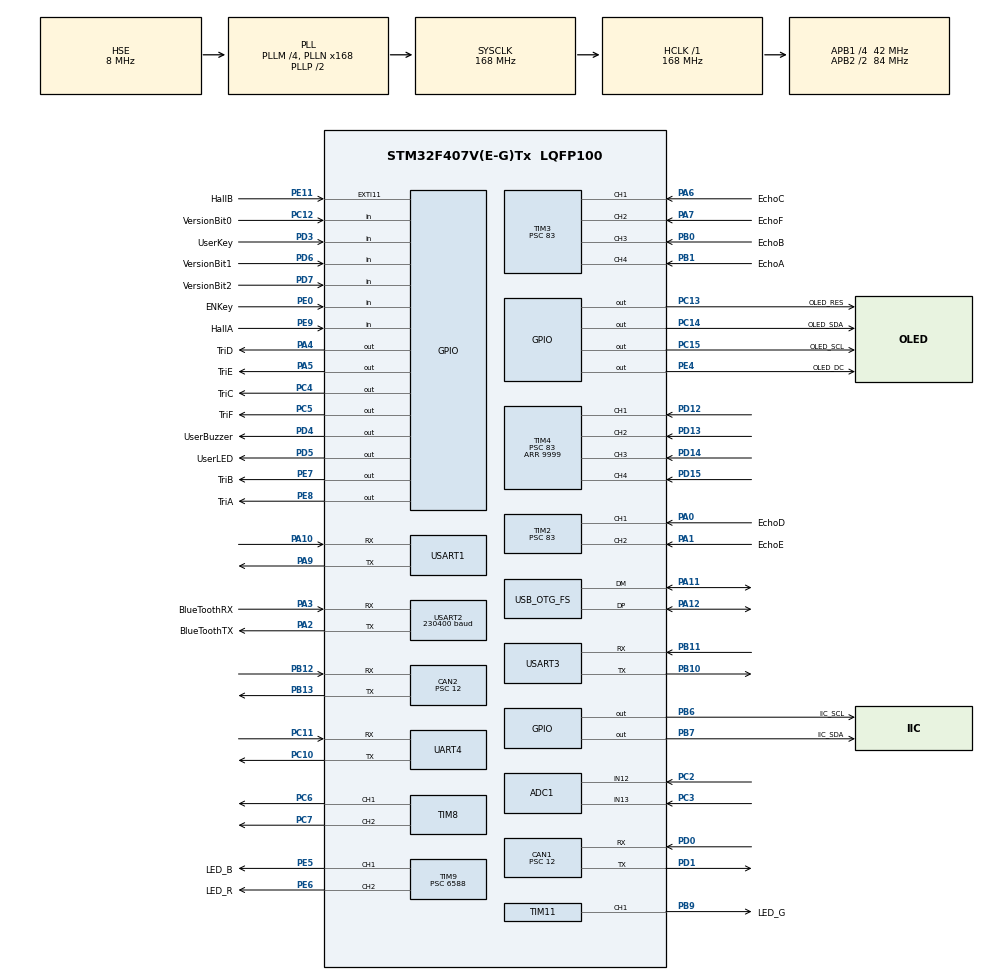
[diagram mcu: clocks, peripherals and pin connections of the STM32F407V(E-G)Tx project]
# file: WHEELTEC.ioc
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ADC1.Channel-0\#ChannelRegularConversion=ADC_CHANNEL_12
ADC1.Channel-1\#ChannelRegularConversion=ADC_CHANNEL_13
ADC1.ClockPrescaler=ADC_CLOCK_SYNC_PCLK_DIV6
ADC1.ContinuousConvMode=ENABLE
ADC1.DMAContinuousRequests=ENABLE
ADC1.NbrOfConversion=2
ADC1.NbrOfConversionFlag=1
ADC1.Rank-0\#ChannelRegularConversion=1
ADC1.Rank-1\#ChannelRegularConversion=2
ADC1.SamplingTime-0\#ChannelRegularConversion=ADC_SAMPLETIME_480CYCLES
ADC1.SamplingTime-1\#ChannelRegularConversion=ADC_SAMPLETIME_480CYCLES
ADC1.ScanConvMode=ENABLE
ADC1.master=1
CAN1.BS1=CAN_BS1_3TQ
CAN1.BS2=CAN_BS2_3TQ
CAN1.CalculateBaudRate=500000
CAN1.CalculateTimeBit=2000
CAN1.CalculateTimeQuantum=285.7142857142857
CAN1.Prescaler=12
CAN1.SJW=CAN_SJW_1TQ
CAN2.BS1=CAN_BS1_3TQ
CAN2.BS2=CAN_BS2_3TQ
CAN2.CalculateBaudRate=500000
CAN2.CalculateTimeBit=2000
CAN2.CalculateTimeQuantum=285.7142857142857
CAN2.Prescaler=12
Dma.ADC1.0.Direction=DMA_PERIPH_TO_MEMORY
Dma.ADC1.0.FIFOMode=DMA_FIFOMODE_DISABLE
Dma.ADC1.0.Instance=DMA2_Stream0
Dma.ADC1.0.MemDataAlignment=DMA_MDATAALIGN_HALFWORD
Dma.ADC1.0.MemInc=DMA_MINC_ENABLE
Dma.ADC1.0.Mode=DMA_CIRCULAR
Dma.ADC1.0.PeriphDataAlignment=DMA_PDATAALIGN_HALFWORD
Dma.ADC1.0.PeriphInc=DMA_PINC_DISABLE
Dma.ADC1.0.Priority=DMA_PRIORITY_LOW
Dma.Request0=ADC1
Dma.Request1=USART2_TX
Dma.Request2=UART4_TX
Dma.Request3=USART1_TX
Dma.Request4=USART3_RX
Dma.UART4_TX.2.Direction=DMA_MEMORY_TO_PERIPH
Dma.UART4_TX.2.FIFOMode=DMA_FIFOMODE_DISABLE
Dma.UART4_TX.2.Instance=DMA1_Stream4
Dma.UART4_TX.2.MemDataAlignment=DMA_MDATAALIGN_BYTE
Dma.UART4_TX.2.MemInc=DMA_MINC_ENABLE
Dma.UART4_TX.2.Mode=DMA_NORMAL
Dma.UART4_TX.2.PeriphDataAlignment=DMA_PDATAALIGN_BYTE
Dma.UART4_TX.2.PeriphInc=DMA_PINC_DISABLE
Dma.UART4_TX.2.Priority=DMA_PRIORITY_LOW
Dma.USART1_TX.3.Direction=DMA_MEMORY_TO_PERIPH
Dma.USART1_TX.3.FIFOMode=DMA_FIFOMODE_DISABLE
Dma.USART1_TX.3.Instance=DMA2_Stream7
Dma.USART1_TX.3.MemDataAlignment=DMA_MDATAALIGN_BYTE
Dma.USART1_TX.3.MemInc=DMA_MINC_ENABLE
Dma.USART1_TX.3.Mode=DMA_NORMAL
Dma.USART1_TX.3.PeriphDataAlignment=DMA_PDATAALIGN_BYTE
Dma.USART1_TX.3.PeriphInc=DMA_PINC_DISABLE
Dma.USART1_TX.3.Priority=DMA_PRIORITY_LOW
Dma.USART2_TX.1.Direction=DMA_MEMORY_TO_PERIPH
Dma.USART2_TX.1.FIFOMode=DMA_FIFOMODE_DISABLE
Dma.USART2_TX.1.Instance=DMA1_Stream6
Dma.USART2_TX.1.MemDataAlignment=DMA_MDATAALIGN_BYTE
Dma.USART2_TX.1.MemInc=DMA_MINC_ENABLE
Dma.USART2_TX.1.Mode=DMA_NORMAL
Dma.USART2_TX.1.PeriphDataAlignment=DMA_PDATAALIGN_BYTE
Dma.USART2_TX.1.PeriphInc=DMA_PINC_DISABLE
Dma.USART2_TX.1.Priority=DMA_PRIORITY_LOW
Dma.USART3_RX.4.Direction=DMA_PERIPH_TO_MEMORY
Dma.USART3_RX.4.FIFOMode=DMA_FIFOMODE_DISABLE
Dma.USART3_RX.4.Instance=DMA1_Stream1
Dma.USART3_RX.4.MemDataAlignment=DMA_MDATAALIGN_BYTE
Dma.USART3_RX.4.MemInc=DMA_MINC_ENABLE
Dma.USART3_RX.4.Mode=DMA_NORMAL
Dma.USART3_RX.4.PeriphDataAlignment=DMA_PDATAALIGN_BYTE
Dma.USART3_RX.4.PeriphInc=DMA_PINC_DISABLE
Dma.USART3_RX.4.Priority=DMA_PRIORITY_LOW
FREERTOS.Tasks01=InitTask,32,128,StartInitTask,Default,NULL,Dynamic,NULL,NULL
FREERTOS.configCHECK_FOR_STACK_OVERFLOW=2
FREERTOS.configENABLE_FPU=1
FREERTOS.configGENERATE_RUN_TIME_STATS=1
FREERTOS.configTOTAL_HEAP_SIZE=51200
FREERTOS.configUSE_DAEMON_TASK_STARTUP_HOOK=0
FREERTOS.configUSE_IDLE_HOOK=1
FREERTOS.configUSE_MALLOC_FAILED_HOOK=1
FREERTOS.configUSE_STATS_FORMATTING_FUNCTIONS=1
Mcu.Family=STM32F4
Mcu.Name=STM32F407V(E-G)Tx
Mcu.Package=LQFP100
NVIC.CAN1_RX0_IRQn=true\:5\:0\:false\:false\:true\:true\:true\:true\:true
NVIC.CAN2_RX1_IRQn=true\:5\:0\:false\:false\:true\:true\:true\:true\:true
NVIC.DMA1_Stream1_IRQn=true\:5\:0\:false\:false\:true\:true\:false\:true\:true
NVIC.DMA1_Stream4_IRQn=true\:5\:0\:false\:false\:true\:true\:false\:true\:true
NVIC.DMA1_Stream6_IRQn=true\:5\:0\:false\:false\:true\:true\:false\:true\:true
NVIC.DMA2_Stream0_IRQn=true\:5\:0\:false\:false\:true\:true\:false\:true\:true
NVIC.DMA2_Stream7_IRQn=true\:5\:0\:false\:false\:true\:true\:false\:true\:true
NVIC.EXTI9_5_IRQn=true\:5\:0\:false\:false\:true\:true\:true\:true\:true
NVIC.OTG_FS_IRQn=true\:5\:0\:false\:false\:true\:true\:false\:true\:true
NVIC.PriorityGroup=NVIC_PRIORITYGROUP_4
NVIC.TIM2_IRQn=true\:5\:0\:false\:false\:true\:true\:true\:true\:true
NVIC.TIM3_IRQn=true\:5\:0\:false\:false\:true\:true\:true\:true\:true
NVIC.TIM4_IRQn=true\:5\:0\:false\:false\:true\:true\:true\:true\:true
NVIC.TIM7_IRQn=true\:15\:0\:true\:false\:true\:false\:false\:true\:true
NVIC.TimeBase=TIM7_IRQn
NVIC.TimeBaseIP=TIM7
NVIC.UART4_IRQn=true\:5\:0\:false\:false\:true\:true\:true\:true\:true
NVIC.USART1_IRQn=true\:5\:0\:false\:false\:true\:true\:true\:true\:true
NVIC.USART2_IRQn=true\:5\:0\:false\:false\:true\:true\:true\:true\:true
NVIC.USART3_IRQn=true\:5\:0\:false\:false\:true\:true\:true\:true\:true
PA0-WKUP.GPIO_Label=EchoD
PA0-WKUP.Signal=S_TIM2_CH1_ETR
PA1.GPIO_Label=EchoE
PA1.Signal=S_TIM2_CH2
PA10.Mode=Asynchronous
PA10.Signal=USART1_RX
PA11.Mode=Host_Only
PA11.Signal=USB_OTG_FS_DM
PA12.Mode=Host_Only
PA12.Signal=USB_OTG_FS_DP
PA13.Mode=Serial_Wire
PA13.Signal=SYS_JTMS-SWDIO
PA14.Mode=Serial_Wire
PA14.Signal=SYS_JTCK-SWCLK
PA2.GPIO_Label=BlueToothTX
PA2.Mode=Asynchronous
PA2.Signal=USART2_TX
PA3.GPIO_Label=BlueToothRX
PA3.Mode=Asynchronous
PA3.Signal=USART2_RX
PA4.GPIO_Label=TriD
PA4.GPIO_Speed=GPIO_SPEED_FREQ_VERY_HIGH
PA4.PinState=GPIO_PIN_SET
PA4.Signal=GPIO_Output
PA5.GPIO_Label=TriE
PA5.GPIO_Speed=GPIO_SPEED_FREQ_VERY_HIGH
PA5.PinState=GPIO_PIN_SET
PA5.Signal=GPIO_Output
PA6.GPIO_Label=EchoC
PA6.Signal=S_TIM3_CH1
PA7.GPIO_Label=EchoF
PA7.Signal=S_TIM3_CH2
PA9.Mode=Asynchronous
PA9.Signal=USART1_TX
PB0.GPIO_Label=EchoB
PB0.Signal=S_TIM3_CH3
PB1.GPIO_Label=EchoA
PB1.Signal=S_TIM3_CH4
PB10.Mode=Asynchronous
PB10.Signal=USART3_TX
PB11.Mode=Asynchronous
PB11.Signal=USART3_RX
PB12.Mode=CAN_Activate
PB12.Signal=CAN2_RX
PB13.Mode=CAN_Activate
PB13.Signal=CAN2_TX
PB6.GPIO_Label=IIC_SCL
PB6.GPIO_PuPd=GPIO_NOPULL
PB6.GPIO_Speed=GPIO_SPEED_FREQ_VERY_HIGH
PB6.PinState=GPIO_PIN_SET
PB6.Signal=GPIO_Output
PB7.GPIO_Label=IIC_SDA
PB7.GPIO_Speed=GPIO_SPEED_FREQ_VERY_HIGH
PB7.PinState=GPIO_PIN_SET
PB7.Signal=GPIO_Output
PB9.GPIO_Label=LED_G
PB9.Signal=S_TIM11_CH1
PC10.Mode=Asynchronous
PC10.Signal=UART4_TX
PC11.Mode=Asynchronous
PC11.Signal=UART4_RX
PC12.GPIO_Label=VersionBit0
PC12.GPIO_PuPd=GPIO_PULLUP
PC12.Signal=GPIO_Input
PC13-ANTI_TAMP.GPIO_Label=OLED_RES
PC13-ANTI_TAMP.Signal=GPIO_Output
PC14-OSC32_IN.GPIO_Label=OLED_SDA
PC14-OSC32_IN.Signal=GPIO_Output
PC15-OSC32_OUT.GPIO_Label=OLED_SCL
PC15-OSC32_OUT.Signal=GPIO_Output
PC2.Signal=ADCx_IN12
PC3.Signal=ADCx_IN13
PC4.GPIO_Label=TriC
PC4.GPIO_Speed=GPIO_SPEED_FREQ_VERY_HIGH
PC4.PinState=GPIO_PIN_SET
PC4.Signal=GPIO_Output
PC5.GPIO_Label=TriF
PC5.GPIO_Speed=GPIO_SPEED_FREQ_VERY_HIGH
PC5.PinState=GPIO_PIN_SET
PC5.Signal=GPIO_Output
PC6.Signal=S_TIM8_CH1
PC7.Signal=S_TIM8_CH2
PD0.Mode=CAN_Activate
PD0.Signal=CAN1_RX
PD1.Mode=CAN_Activate
PD1.Signal=CAN1_TX
PD12.Signal=S_TIM4_CH1
PD13.Signal=S_TIM4_CH2
PD14.Signal=S_TIM4_CH3
PD15.Signal=S_TIM4_CH4
PD3.GPIO_Label=UserKey
PD3.GPIO_PuPd=GPIO_PULLUP
PD3.Signal=GPIO_Input
PD4.GPIO_Label=UserBuzzer
PD4.PinState=GPIO_PIN_RESET
PD4.Signal=GPIO_Output
PD5.GPIO_Label=UserLED
PD5.PinState=GPIO_PIN_SET
PD5.Signal=GPIO_Output
PD6.GPIO_Label=VersionBit1
PD6.GPIO_PuPd=GPIO_PULLUP
PD6.Signal=GPIO_Input
PD7.GPIO_Label=VersionBit2
PD7.GPIO_PuPd=GPIO_PULLUP
PD7.Signal=GPIO_Input
PE0.GPIO_Label=ENKey
PE0.GPIO_Mode=GPIO_MODE_INPUT
PE0.GPIO_PuPd=GPIO_PULLUP
PE0.Signal=GPIO_Input
PE4.GPIO_Label=OLED_DC
PE4.Signal=GPIO_Output
PE5.GPIO_Label=LED_B
PE5.Signal=S_TIM9_CH1
PE6.GPIO_Label=LED_R
PE6.Signal=S_TIM9_CH2
PE7.GPIO_Label=TriB
PE7.GPIO_Speed=GPIO_SPEED_FREQ_VERY_HIGH
PE7.PinState=GPIO_PIN_SET
PE7.Signal=GPIO_Output
PE8.GPIO_Label=TriA
PE8.GPIO_Speed=GPIO_SPEED_FREQ_VERY_HIGH
PE8.PinState=GPIO_PIN_SET
PE8.Signal=GPIO_Output
PE9.GPIO_Label=HallA
PE9.GPIO_Mode=GPIO_MODE_INPUT
PE9.GPIO_PuPd=GPIO_PULLUP
PE9.Signal=GPIO_Input
PE11.GPIO_Label=HallB
PE11.GPIO_Mode=GPIO_MODE_IT_FALLING
PE11.GPIO_PuPd=GPIO_PULLUP
PE11.Signal=GPIO_EXTI11
PH0-OSC_IN.Mode=HSE-External-Oscillator
PH0-OSC_IN.Signal=RCC_OSC_IN
PH1-OSC_OUT.Mode=HSE-External-Oscillator
PH1-OSC_OUT.Signal=RCC_OSC_OUT
ProjectManager.HeapSize=0x200
ProjectManager.StackSize=0x400
ProjectManager.TargetToolchain=MDK-ARM V5.32
RCC.48MHZClocksFreq_Value=48000000
RCC.AHBFreq_Value=168000000
RCC.APB1CLKDivider=RCC_HCLK_DIV4
RCC.APB1Freq_Value=42000000
RCC.APB1TimFreq_Value=84000000
RCC.APB2CLKDivider=RCC_HCLK_DIV2
RCC.APB2Freq_Value=84000000
RCC.APB2TimFreq_Value=168000000
RCC.CortexFreq_Value=168000000
RCC.HCLKFreq_Value=168000000
RCC.HSE_VALUE=8000000
RCC.HSI_VALUE=16000000
RCC.LSE_VALUE=32768
RCC.PLLM=4
RCC.PLLN=168
RCC.PLLQ=7
RCC.SYSCLKFreq_VALUE=168000000
RCC.SYSCLKSource=RCC_SYSCLKSOURCE_PLLCLK
RCC.VCOOutputFreq_Value=336000000
SH.ADCx_IN12.0=ADC1_IN12,IN12
SH.ADCx_IN13.0=ADC1_IN13,IN13
SH.S_TIM11_CH1.0=TIM11_CH1,PWM Generation1 CH1
SH.S_TIM2_CH1_ETR.0=TIM2_CH1,Input_Capture1_from_TI1
SH.S_TIM2_CH2.0=TIM2_CH2,Input_Capture2_from_TI2
SH.S_TIM3_CH1.0=TIM3_CH1,Input_Capture1_from_TI1
SH.S_TIM3_CH2.0=TIM3_CH2,Input_Capture2_from_TI2
SH.S_TIM3_CH3.0=TIM3_CH3,Input_Capture3_from_TI3
SH.S_TIM3_CH4.0=TIM3_CH4,Input_Capture4_from_TI4
SH.S_TIM4_CH1.0=TIM4_CH1,Input_Capture1_from_TI1
SH.S_TIM4_CH2.0=TIM4_CH2,Input_Capture2_from_TI2
SH.S_TIM4_CH3.0=TIM4_CH3,Input_Capture3_from_TI3
SH.S_TIM4_CH4.0=TIM4_CH4,Input_Capture4_from_TI4
SH.S_TIM8_CH1.0=TIM8_CH1,PWM Generation1 CH1
SH.S_TIM8_CH2.0=TIM8_CH2,PWM Generation2 CH2
SH.S_TIM9_CH1.0=TIM9_CH1,PWM Generation1 CH1
SH.S_TIM9_CH2.0=TIM9_CH2,PWM Generation2 CH2
TIM11.Channel=TIM_CHANNEL_1
TIM11.Period=254
TIM11.Prescaler=6588
TIM2.Channel-Input_Capture1_from_TI1=TIM_CHANNEL_1
TIM2.Channel-Input_Capture2_from_TI2=TIM_CHANNEL_2
TIM2.Period=0xffff
TIM2.Prescaler=83
TIM3.Channel-Input_Capture1_from_TI1=TIM_CHANNEL_1
TIM3.Channel-Input_Capture2_from_TI2=TIM_CHANNEL_2
TIM3.Channel-Input_Capture3_from_TI3=TIM_CHANNEL_3
TIM3.Channel-Input_Capture4_from_TI4=TIM_CHANNEL_4
TIM3.Prescaler=83
TIM4.Channel-Input_Capture1_from_TI1=TIM_CHANNEL_1
TIM4.Channel-Input_Capture2_from_TI2=TIM_CHANNEL_2
TIM4.Channel-Input_Capture3_from_TI3=TIM_CHANNEL_3
TIM4.Channel-Input_Capture4_from_TI4=TIM_CHANNEL_4
TIM4.Period=9999
TIM4.Prescaler=83
TIM6.Prescaler=839
TIM8.Channel-PWM\ Generation1\ CH1=TIM_CHANNEL_1
TIM8.Channel-PWM\ Generation2\ CH2=TIM_CHANNEL_2
TIM9.Channel-PWM\ Generation1\ CH1=TIM_CHANNEL_1
TIM9.Channel-PWM\ Generation2\ CH2=TIM_CHANNEL_2
TIM9.Period=254
TIM9.Prescaler=6588
UART4.VirtualMode=Asynchronous
USART1.VirtualMode=VM_ASYNC
USART2.BaudRate=230400
USART2.VirtualMode=VM_ASYNC
USART3.VirtualMode=VM_ASYNC
USB_HOST.SW_VBUS_DRIVE_HID_FS=true
USB_HOST.USBH_DEBUG_LEVEL-HID_FS=0
USB_HOST.USBH_HandleTypeDef-HID_FS=hUsbHostFS
USB_HOST.USBH_MAX_DATA_BUFFER-HID_FS=2048
USB_HOST.USBH_MAX_NUM_SUPPORTED_CLASS-HID_FS=2
USB_HOST.USBH_MAX_SIZE_CONFIGURATION-HID_FS=256
USB_HOST.USBH_PROCESS_STACK_SIZE-HID_FS=1024
USB_HOST.VirtualModeFS=Hid
USB_OTG_FS.VirtualMode=Host_Only
USB_OTG_FS.phy_itface=HCD_PHY_EMBEDDED
VP_FREERTOS_VS_CMSIS_V2.Mode=CMSIS_V2
VP_SYS_VS_tim7.Mode=TIM7
VP_TIM11_VS_ClockSourceINT.Mode=Enable_Timer
VP_TIM2_VS_ClockSourceINT.Mode=Internal
VP_TIM3_VS_ClockSourceINT.Mode=Internal
VP_TIM4_VS_ClockSourceINT.Mode=Internal
VP_TIM6_VS_ClockSourceINT.Mode=Enable_Timer
VP_TIM8_VS_ClockSourceINT.Mode=Internal
VP_TIM9_VS_ClockSourceINT.Mode=Internal
VP_USB_HOST_VS_USB_HOST_HID_FS.Mode=HID_FS
board=custom

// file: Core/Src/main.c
/* USER CODE BEGIN Header */
/**
  ******************************************************************************
  * @file           : main.c
  * @brief          : Main program body
  ******************************************************************************
  * @attention
  *
  * Copyright (c) 2025 STMicroelectronics.
  * All rights reserved.
  *
  * This software is licensed under terms that can be found in the LICENSE file
  * in the root directory of this software component.
  * If no LICENSE file comes with this software, it is provided AS-IS.
  *
  ******************************************************************************
  */
/* USER CODE END Header */
#include "main.h"
#include "cmsis_os.h"
#include "adc.h"
#include "can.h"
#include "dma.h"
#include "tim.h"
#include "usart.h"
#include "usb_host.h"
#include "gpio.h"

/* USER CODE BEGIN Includes */
#include <stdio.h>

//bsp
#include "bsp_oled.h"
#include "bsp_dwt.h"
#include "bsp_can.h"
#include "bsp_adc.h"
#include "bsp_flash.h"

#include "hall_speed.h"
#include "servo_basic_control.h"
#include "robot_select_init.h"

/* USER CODE END Includes */

/* USER CODE BEGIN PV */

static uint8_t HardWareVersion = HW_UnKnown; //绯荤粺纭欢鐗堟湰

uint8_t BlueToothBuffer = 0;//钃濈墮涓插彛鎺ユ敹缂撳啿
uint8_t rosbuffer = 0;      //ROS涓插彛鎺ユ敹缂撳啿鍖?
uint8_t usart1_buffer = 0;  //涓插彛1鎺ユ敹缂撳啿鍖?
uint8_t rs485_buffer = 0;   //485鎺ユ敹缂撳啿鍖?

DebugType_t g_sys_debug = { 0 }; //鍏ㄥ眬璋冭瘯鍙橀噺
/* USER CODE END PV */

void SystemClock_Config(void);
void MX_FREERTOS_Init(void);

int main(void)
{

  /* MCU Configuration--------------------------------------------------------*/

  /* Reset of all peripherals, Initializes the Flash interface and the Systick. */
  HAL_Init();

  /* Configure the system clock */
  SystemClock_Config();

  /* Initialize all configured peripherals */
  MX_GPIO_Init();
  MX_DMA_Init();
  MX_USART1_UART_Init();
  MX_USART2_UART_Init();
  MX_USART3_UART_Init();
  MX_UART4_Init();
  MX_TIM2_Init();
  MX_TIM3_Init();
  MX_TIM4_Init();
  MX_TIM6_Init();
  MX_TIM9_Init();
  MX_TIM11_Init();
  MX_ADC1_Init();
  MX_CAN1_Init();
  MX_CAN2_Init();
  MX_TIM8_Init();
  /* USER CODE BEGIN 2 */

  /* Initialize Ackermann servo/ESC control state */
  ServoBasic_Init();

		//DWT瀹氭椂鍣ㄥ垵濮嬪寲,鐢ㄤ簬瀹炵幇ms銆乽s寤舵椂鍑芥暟
		DWT_Init();

		//鍒濆鍖栭湇灏旇疆閫熺姸鎬侊紝璇ュ姛鑳藉湪 PE9/PE11 EXTI 杈撳叆涓婂伐浣?
		HallSpeed_Init();

		//ADC鐢ㄦ埛閰嶇疆鍒濆鍖?
		ADC_Userconfig_Init();

	//鍚姩FreeRTOS绯荤粺璋冭瘯瀹氭椂鍣?
	HAL_TIM_Base_Start(&htim6);

	//OLED灞忓箷鍒濆鍖?
	pOLEDInterface_t oled = &UserOLED;
	oled->init();

	//C63X纭欢鐗堟湰纭畾(閫氳繃鐗堟湰io鍙?纭纭欢鐗堟湰)
	uint8_t Version = 0;
	Version |= (HAL_GPIO_ReadPin(VersionBit2_GPIO_Port,VersionBit2_Pin))<<2;
	Version |= (HAL_GPIO_ReadPin(VersionBit1_GPIO_Port,VersionBit1_Pin))<<1;
	Version |= (HAL_GPIO_ReadPin(VersionBit0_GPIO_Port,VersionBit0_Pin))<<0;

	if( Version == 0 )
	{
		HardWareVersion = HW_1_1;
	}
	else if( Version == 7)
	{
		HardWareVersion = HW_1_0;

		//鍙嶅垵濮嬪寲V2.0鐗堟湰鐨凜AN寮曡剼
		HAL_GPIO_DeInit(GPIOD, GPIO_PIN_0|GPIO_PIN_1);

		//鍒濆鍖朧1.0鐗堟湰CAN寮曡剼
		GPIO_InitTypeDef GPIO_InitStruct = {0};
		__HAL_RCC_GPIOA_CLK_ENABLE();
		GPIO_InitStruct.Pin = GPIO_PIN_11|GPIO_PIN_12;
		GPIO_InitStruct.Mode = GPIO_MODE_AF_PP;
		GPIO_InitStruct.Pull = GPIO_NOPULL;
		GPIO_InitStruct.Speed = GPIO_SPEED_FREQ_VERY_HIGH;
		GPIO_InitStruct.Alternate = GPIO_AF9_CAN1;
		HAL_GPIO_Init(GPIOA, &GPIO_InitStruct);

		//V1.0鐗堟湰鎬ュ仠寮€鍏?
		HAL_GPIO_DeInit(ENKey_GPIO_Port,ENKey_Pin);
		__HAL_RCC_GPIOD_CLK_ENABLE();
		GPIO_InitStruct.Pin = ENKey_V1_0_Pin;
		GPIO_InitStruct.Mode = GPIO_MODE_INPUT;
		GPIO_InitStruct.Pull = GPIO_PULLUP;
		HAL_GPIO_Init(ENKey_V1_0_GPIO_Port, &GPIO_InitStruct);

		//V1.0鐗堟湰鎸夐敭
		HAL_GPIO_DeInit(UserKey_V1_0_Port,UserKey_V1_0_Pin);
		HAL_GPIO_DeInit(UserKey_GPIO_Port,UserKey_Pin);
		__HAL_RCC_GPIOD_CLK_ENABLE();
		GPIO_InitStruct.Pin = UserKey_V1_0_Pin;
		GPIO_InitStruct.Mode = GPIO_MODE_INPUT;
		GPIO_InitStruct.Pull = GPIO_PULLUP;
		HAL_GPIO_Init(UserKey_V1_0_Port, &GPIO_InitStruct);
	}
	else
	{
		oled->ShowString(0,0,"unknown hardware-version.");
		oled->ShowString(0,35,"please reset and-retry.");
		oled->RefreshGram();
		while(1)
		{
			HAL_GPIO_TogglePin(UserBuzzer_GPIO_Port,UserBuzzer_Pin);
			HAL_Delay(500);
		}
	}

	//寮€鍚埅妯￠仴鎺х浉鍏冲畾鏃跺櫒鎹曡幏鍔熻兘
	HAL_TIM_IC_Start_IT(&htim4,TIM_CHANNEL_1);
	HAL_TIM_IC_Start_IT(&htim4,TIM_CHANNEL_2);
	HAL_TIM_IC_Start_IT(&htim4,TIM_CHANNEL_3);

	//鍚姩涓插彛鎺ユ敹涓柇
	HAL_UART_Receive_IT(&huart2,&BlueToothBuffer,1);
	HAL_UART_Receive_IT(&huart4,&rosbuffer,1);
	HAL_UART_Receive_IT(&huart1,&usart1_buffer,1);
	HAL_UART_Receive_IT(&huart3,&rs485_buffer,1);

	//485鎺ュ彛娴嬭瘯浣跨敤
//	uint8_t _485debug[] = {"hello c63x! RS485 Test Info"};
//	HAL_UART_Transmit(&huart3,_485debug,sizeof(_485debug)/sizeof(_485debug[0]),500);

	//閫氳繃鐢典綅鍣ㄧ‘璁よ溅鍨?
	HAL_Delay(500);
	Robot_Select();

	//璇诲彇鐢ㄦ埛淇濆瓨鐨勯粯璁ら€熷害鍊?
	uint32_t flashdata[2];
	User_Flash_ReadParam((uint32_t *)flashdata,2);

	//灏忚溅榛樿閬ユ帶閫熷害鍊?
	if( flashdata[0]!=0xFFFFFFFF )
	{
		if( flashdata[0]<=3500 )
			RobotControlParam.defalutSpeed = flashdata[0];
	}

	//绾犲亸绯绘暟鍊?
	if( flashdata[1]!=0xFFFFFFFF )
	{
		if( flashdata[1]<=100 )
			RobotControlParam.LineDiffParam = flashdata[1];
	}

  /* USER CODE END 2 */

  /* Init scheduler */
  osKernelInitialize();  /* Call init function for freertos objects (in cmsis_os2.c) */
  MX_FREERTOS_Init();

  /* Start scheduler */
  osKernelStart();

  /* We should never get here as control is now taken by the scheduler */

  /* Infinite loop */
  while (1)
  {

  }
}

void SystemClock_Config(void)
{
  RCC_OscInitTypeDef RCC_OscInitStruct = {0};
  RCC_ClkInitTypeDef RCC_ClkInitStruct = {0};

  /** Configure the main internal regulator output voltage
  */
  __HAL_RCC_PWR_CLK_ENABLE();
  __HAL_PWR_VOLTAGESCALING_CONFIG(PWR_REGULATOR_VOLTAGE_SCALE1);

  /** Initializes the RCC Oscillators according to the specified parameters
  * in the RCC_OscInitTypeDef structure.
  */
  RCC_OscInitStruct.OscillatorType = RCC_OSCILLATORTYPE_HSE;
  RCC_OscInitStruct.HSEState = RCC_HSE_ON;
  RCC_OscInitStruct.PLL.PLLState = RCC_PLL_ON;
  RCC_OscInitStruct.PLL.PLLSource = RCC_PLLSOURCE_HSE;
  RCC_OscInitStruct.PLL.PLLM = 4;
  RCC_OscInitStruct.PLL.PLLN = 168;
  RCC_OscInitStruct.PLL.PLLP = RCC_PLLP_DIV2;
  RCC_OscInitStruct.PLL.PLLQ = 7;
  if (HAL_RCC_OscConfig(&RCC_OscInitStruct) != HAL_OK)
  {
    Error_Handler();
  }

  /** Initializes the CPU, AHB and APB buses clocks
  */
  RCC_ClkInitStruct.ClockType = RCC_CLOCKTYPE_HCLK|RCC_CLOCKTYPE_SYSCLK
                              |RCC_CLOCKTYPE_PCLK1|RCC_CLOCKTYPE_PCLK2;
  RCC_ClkInitStruct.SYSCLKSource = RCC_SYSCLKSOURCE_PLLCLK;
  RCC_ClkInitStruct.AHBCLKDivider = RCC_SYSCLK_DIV1;
  RCC_ClkInitStruct.APB1CLKDivider = RCC_HCLK_DIV4;
  RCC_ClkInitStruct.APB2CLKDivider = RCC_HCLK_DIV2;

  if (HAL_RCC_ClockConfig(&RCC_ClkInitStruct, FLASH_LATENCY_5) != HAL_OK)
  {
    Error_Handler();
  }
}

/* USER CODE BEGIN 4 */

UART_HandleTypeDef *DebugSerial = &huart1;

//printf鍑芥暟瀹炵幇
int fputc(int ch,FILE* stream)
{
	while( HAL_OK != HAL_UART_Transmit(DebugSerial,(const uint8_t *)&ch,1,100));
	return ch;
}

//鑾峰彇纭欢鐗堟湰
uint8_t get_HardWareVersion(void)
{
	return HardWareVersion;
}

//鑾峰彇鎬ュ仠寮€鍏崇姸鎬?涓庣増鏈浉鍏?
GPIO_PinState get_EnKeyState(void)
{
	if( HardWareVersion == HW_1_0 )
	{
		return HAL_GPIO_ReadPin(ENKey_V1_0_GPIO_Port,ENKey_V1_0_Pin);
	}
	else if( HardWareVersion == HW_1_1 )
	{
		return HAL_GPIO_ReadPin(ENKey_GPIO_Port,ENKey_Pin);
	}

	return GPIO_PIN_RESET;
}

/* USER CODE END 4 */

void HAL_TIM_PeriodElapsedCallback(TIM_HandleTypeDef *htim)
{
  if (htim->Instance == TIM7)
  {
    HAL_IncTick();
  }
}

void Error_Handler(void)
{
  __disable_irq();
  while (1)
  {
  }
}

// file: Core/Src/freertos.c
/* USER CODE BEGIN Header */
/**
  ******************************************************************************
  * File Name          : freertos.c
  * Description        : Code for freertos applications
  ******************************************************************************
  * @attention
  *
  * Copyright (c) 2025 STMicroelectronics.
  * All rights reserved.
  *
  * This software is licensed under terms that can be found in the LICENSE file
  * in the root directory of this software component.
  * If no LICENSE file comes with this software, it is provided AS-IS.
  *
  ******************************************************************************
  */
/* USER CODE END Header */

#include "FreeRTOS.h"
#include "task.h"
#include "main.h"
#include "cmsis_os.h"

/* USER CODE BEGIN Includes */

//C Include File
#include <stdio.h>

//FreeRTOS Include File
#include "queue.h"

//BSP Include File
#include "bsp_oled.h"
#include "bsp_RTOSdebug.h"
#include "bsp_ServoDrive.h"
#include "bsp_RGBLight.h"
#include "bsp_can.h"
#include "bsp_ServoDrive.h"
#include "bsp_buzzer.h"

//APP Include File
#include "sensor_ranger.h"
#include "robot_select_init.h"
#include "servo_basic_task.h"

/* USER CODE END Includes */

/* USER CODE BEGIN PD */

//FreeRTOS系统调试
#define userconfig_OPEN_STACK_CHECK     0  //开启任务栈大小检查打印
#define userconfig_OPEN_CPU_USAGE_CHECK 0  //开启检查CPU占比打印
#define userconfig_OPEN_CHECK_HEAPSIZE  0  //检查剩余的堆大小

/* USER CODE END PD */

/* USER CODE BEGIN Variables */

QueueHandle_t g_xQueueCANopenCallback = NULL;

//蓝牙数据队列
QueueHandle_t g_xQueueBlueTooth = NULL;

//ROS数据队列
QueueHandle_t  g_xQueueROSserial = NULL;

//自动回充队列数据
QueueHandle_t g_xQueueAutoRecharge = NULL;

TaskHandle_t g_reportErrTaskHandle = NULL;

/* USER CODE END Variables */
/* Definitions for InitTask */
osThreadId_t InitTaskHandle;
const osThreadAttr_t InitTask_attributes = {
  .name = "InitTask",
  .stack_size = 128 * 4,
  .priority = (osPriority_t) osPriorityAboveNormal,
};

/* USER CODE BEGIN FunctionPrototypes */

//FreeRTOS系统调试任务
#if ( 1 == userconfig_OPEN_CPU_USAGE_CHECK ) || ( 1 == userconfig_OPEN_STACK_CHECK ) || ( 1 == userconfig_OPEN_CHECK_HEAPSIZE )
void CpuUsageCheckTask(void *param);
#endif

//任务函数声明
void ultrasonic_task(void* param);
void show_task(void* param);
void ImuTask(void* param);
void BlueToothControlTask(void* param);
void SerialControlTask(void* param);
void RobotControl_task(void* param);
void AutoRechargeTask(void* param);
void data_task(void* param);
void RobotDataTransmitTask(void* param);
void APPshow_task(void* param);
void HeartbeatTask(void* param);
void ReportErrTask(void* param);
void RGBControl_task(void* param);

/* USER CODE END FunctionPrototypes */

void StartInitTask(void *argument);

extern void MX_USB_HOST_Init(void);
void MX_FREERTOS_Init(void); /* (MISRA C 2004 rule 8.1) */

/* Hook prototypes */
void configureTimerForRunTimeStats(void);
unsigned long getRunTimeCounterValue(void);
void vApplicationIdleHook(void);
void vApplicationStackOverflowHook(xTaskHandle xTask, signed char *pcTaskName);
void vApplicationMallocFailedHook(void);

/* USER CODE BEGIN 1 */
/* Functions needed when configGENERATE_RUN_TIME_STATS is on */
__weak void configureTimerForRunTimeStats(void)
{
	//使用cpu占比计时器前初始化内容
	TIM6->CNT = 0;
}

__weak unsigned long getRunTimeCounterValue(void)
{
	static unsigned long time = 0 ;
	static uint16_t lasttime = 0;
	static uint16_t nowtime = 0;

	nowtime = TIM6->CNT; //获得当前计数值

	//如果本次计数值小于上次计数值，说明发生了定时器计数溢出
	if( nowtime < lasttime )
	{
		time += (nowtime + 0xffff - lasttime); //溢出后的时间增量
	}
	else time += ( nowtime - lasttime ) ; //未发生溢出，增量为本次时间-上次时间

	lasttime = nowtime;

	return time;
}
/* USER CODE END 1 */

/* USER CODE BEGIN 2 */
void vApplicationIdleHook( void )
{
   /* vApplicationIdleHook() will only be called if configUSE_IDLE_HOOK is set
   to 1 in FreeRTOSConfig.h. It will be called on each iteration of the idle
   task. It is essential that code added to this hook function never attempts
   to block in any way (for example, call xQueueReceive() with a block time
   specified, or call vTaskDelay()). If the application makes use of the
   vTaskDelete() API function (as this demo application does) then it is also
   important that vApplicationIdleHook() is permitted to return to its calling
   function, because it is the responsibility of the idle task to clean up
   memory allocated by the kernel to any task that has since been deleted. */

	//空闲任务钩子函数
}
/* USER CODE END 2 */

/* USER CODE BEGIN 4 */
void vApplicationStackOverflowHook(xTaskHandle xTask, signed char *pcTaskName)
{
   /* Run time stack overflow checking is performed if
   configCHECK_FOR_STACK_OVERFLOW is defined to 1 or 2. This hook function is
   called if a stack overflow is detected. */

	//任务栈溢出警告
	printf("%s stack overflow\r\n",pcTaskName);
}
/* USER CODE END 4 */

/* USER CODE BEGIN 5 */
void vApplicationMallocFailedHook(void)
{
   /* vApplicationMallocFailedHook() will only be called if
   configUSE_MALLOC_FAILED_HOOK is set to 1 in FreeRTOSConfig.h. It is a hook
   function that will get called if a call to pvPortMalloc() fails.
   pvPortMalloc() is called internally by the kernel whenever a task, queue,
   timer or semaphore is created. It is also called by various parts of the
   demo application. If heap_1.c or heap_2.c are used, then the size of the
   heap available to pvPortMalloc() is defined by configTOTAL_HEAP_SIZE in
   FreeRTOSConfig.h, and the xPortGetFreeHeapSize() API function can be used
   to query the size of free heap space that remains (although it does not
   provide information on how the remaining heap might be fragmented). */

	//内存分配失败警告
	printf("malloc failed.check heapsize\r\n");
}
/* USER CODE END 5 */

void MX_FREERTOS_Init(void) {

  /* USER CODE BEGIN RTOS_QUEUES */
  /* add queues, ... */
	g_xQueueBlueTooth = xQueueCreate(50,sizeof(char));//蓝牙数据队列
	g_xQueueROSserial = xQueueCreate(50,sizeof(char));//ROS数据队列
	g_xQueueAutoRecharge = xQueueCreate(1,sizeof(CANmsgType_t));
	ServoBasic_TaskInit();

  /* USER CODE END RTOS_QUEUES */

  /* Create the thread(s) */
  /* creation of InitTask */
  InitTaskHandle = osThreadNew(StartInitTask, NULL, &InitTask_attributes);

  /* USER CODE BEGIN RTOS_THREADS */
  /* add threads, ... */
  //servo basic PWM control task (high priority)
  xTaskCreate(ServoBasic_Task,"ServoTask",128*2,NULL,osPriorityHigh,NULL);

  //小车控制任务
  xTaskCreate(RobotControl_task,"robotcontrol",128*4,NULL,osPriorityNormal1,NULL);

  //超声波数据采集任务
  xTaskCreate(ultrasonic_task,"ultraTask",128*2,NULL,osPriorityNormal,NULL);

  //OLED显示任务
  xTaskCreate(show_task,"showTask",128*4,NULL,osPriorityBelowNormal7,NULL);

  //APP显示任务
  xTaskCreate(APPshow_task,"AppShow",128*2,NULL,osPriorityBelowNormal7,NULL);

  //陀螺仪数据获取
  xTaskCreate(ImuTask,"ImuTask",128*4,NULL,osPriorityNormal,NULL);

  //蓝牙数据解析任务
  xTaskCreate(BlueToothControlTask,"BTControlTask",128*2,NULL,osPriorityNormal,NULL);

  //ROS串口数据解析任务
  xTaskCreate(SerialControlTask,"SerialConTask",128*2,NULL,osPriorityNormal,NULL);

  //自动回充设备数据解析任务
  xTaskCreate(AutoRechargeTask,"AutoRechargeTask",128*2,NULL,osPriorityNormal,NULL);

  //数据外发任务
  xTaskCreate(RobotDataTransmitTask,"transmit_task",128*4,NULL,osPriorityNormal,NULL);

  //RGB灯带管理任务
  xTaskCreate(RGBControl_task,"RGB_task",128*2,NULL,osPriorityBelowNormal7,NULL);

  //CANopen心跳报文处理任务
  xTaskCreate(HeartbeatTask,"HeartbeatTask",128,NULL,osPriorityNormal1,NULL);

  //小车自检上报调试任务
  xTaskCreate(ReportErrTask,"ReportErrTask",128*4,NULL,osPriorityNormal,&g_reportErrTaskHandle);

	//FreeRTOS调试任务
	#if ( 1 == userconfig_OPEN_CPU_USAGE_CHECK ) || ( 1 == userconfig_OPEN_STACK_CHECK ) || ( 1 == userconfig_OPEN_CHECK_HEAPSIZE )
	 static uint16_t delaytime = 5000;//打印时间间隔，单位tick
	 xTaskCreate(CpuUsageCheckTask,"DebugTask",128, &delaytime ,osPriorityAboveNormal,NULL);
	#endif
  /* USER CODE END RTOS_THREADS */

}

void StartInitTask(void *argument)
{
  /* init code for USB_HOST */
  MX_USB_HOST_Init();
  /* USER CODE BEGIN StartInitTask */
  /* Infinite loop */

	//初始化任务，用于初始化部分依赖于FreeRTOS内核的项目

	//CAN滤波器初始化
	pCANInterface_t can = &UserCAN1Dev;
	can->init();
	can = &UserCAN2Dev;
	can->init();

	//开机等待驱动器就绪
	HAL_Delay(1200);

	//关闭CANopen所有映射关系,防止数据干扰
	uint8_t PreOp[8]= {0x80, 0x00, 0x00, 0x00, 0x00, 0x00, 0x00, 0x00};
	can = &UserCAN2Dev;
	can->sendStd(0x00,PreOp,8);
	//启用反馈队列准备配置
	g_xQueueCANopenCallback = xQueueCreate(1,sizeof(CANmsgType_t));

	//根据车型驱动数量初始化对应驱动器
	for(uint8_t i=0;i<RobotHardWareParam.driveCounts;i++)
	{
		ServoDriver_Init(g_ServoDriveList[i]);//从可用驱动列表中加载
	}

	//开机提示
	pBuzzerInterface_t tips = &UserBuzzer;
	tips->AddTask(1,700);

	//初始化完成,删除自身
	vTaskDelete(NULL);
  for(;;)
  {
    osDelay(1);
  }
  /* USER CODE END StartInitTask */
}

/* USER CODE BEGIN Application */

#if ( 1 == userconfig_OPEN_CPU_USAGE_CHECK ) || ( 1 == userconfig_OPEN_STACK_CHECK ) || ( 1 == userconfig_OPEN_CHECK_HEAPSIZE )
void CpuUsageCheckTask(void *param)
{
	uint16_t* delaytime = (uint16_t*)param;
	static char showbuf[500];

	while( 1 )
	{
#if 1 == userconfig_OPEN_CPU_USAGE_CHECK
		//打印CPU占比
		vTaskGetRunTimeStats(showbuf);
		printf("TaskName\tUseTime\tCPU\r\n");
		printf("%s\r\n",showbuf);
		vTaskDelay(*delaytime);
#endif

#if 1 == userconfig_OPEN_STACK_CHECK
		//打印剩余任务栈大小,单位word
		vTaskList(showbuf);
		printf("TaskName\tTaskState\tTaskPrio\tStackSize\tTaskNum\r\n");
		printf("%s\r\n",showbuf);
		vTaskDelay(*delaytime);
#endif

#if 1 == userconfig_OPEN_CHECK_HEAPSIZE
		//打印剩余的堆区大小,单位bytes
		printf("free heap size : %d bytes\r\n\r\n",xPortGetFreeHeapSize());
		vTaskDelay(*delaytime);
#endif
	}
}
#endif

/* USER CODE END Application */
